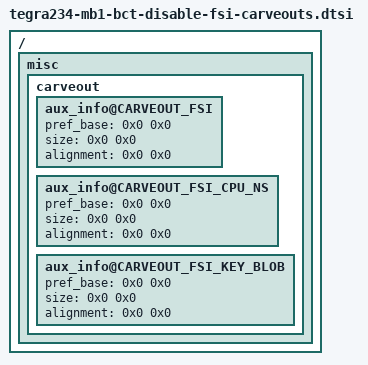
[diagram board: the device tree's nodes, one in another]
/*
 * SPDX-FileCopyrightText: Copyright (c) 2023, NVIDIA CORPORATION & AFFILIATES. All rights reserved.
 * SPDX-License-Identifier: LicenseRef-NvidiaProprietary
 *
 * NVIDIA CORPORATION, its affiliates and licensors retain all intellectual
 * property and proprietary rights in and to this material, related
 * documentation and any modifications thereto. Any use, reproduction,
 * disclosure or distribution of this material and related documentation
 * without an express license agreement from NVIDIA CORPORATION or
 * its affiliates is strictly prohibited.
 */

/* File to Disable FSI Carveouts */

/ {
	misc {
		carveout {
			aux_info@CARVEOUT_FSI {
				pref_base = <0x0 0x0>;
				size = <0x0 0x0>; // 0MB
				alignment = <0x0 0x0>; // 0MB
			};
			aux_info@CARVEOUT_FSI_CPU_NS {
				pref_base = <0x0 0x0>;
				size = <0x0 0x0>; // 0MB
				alignment = <0x0 0x0>; // 0MB
			};
			aux_info@CARVEOUT_FSI_KEY_BLOB {
				pref_base = <0x0 0x0>;
				size = <0x0 0x0>; // 0KB
				alignment = <0x0 0x0>; // 0KB
			};
		};
	};
};
